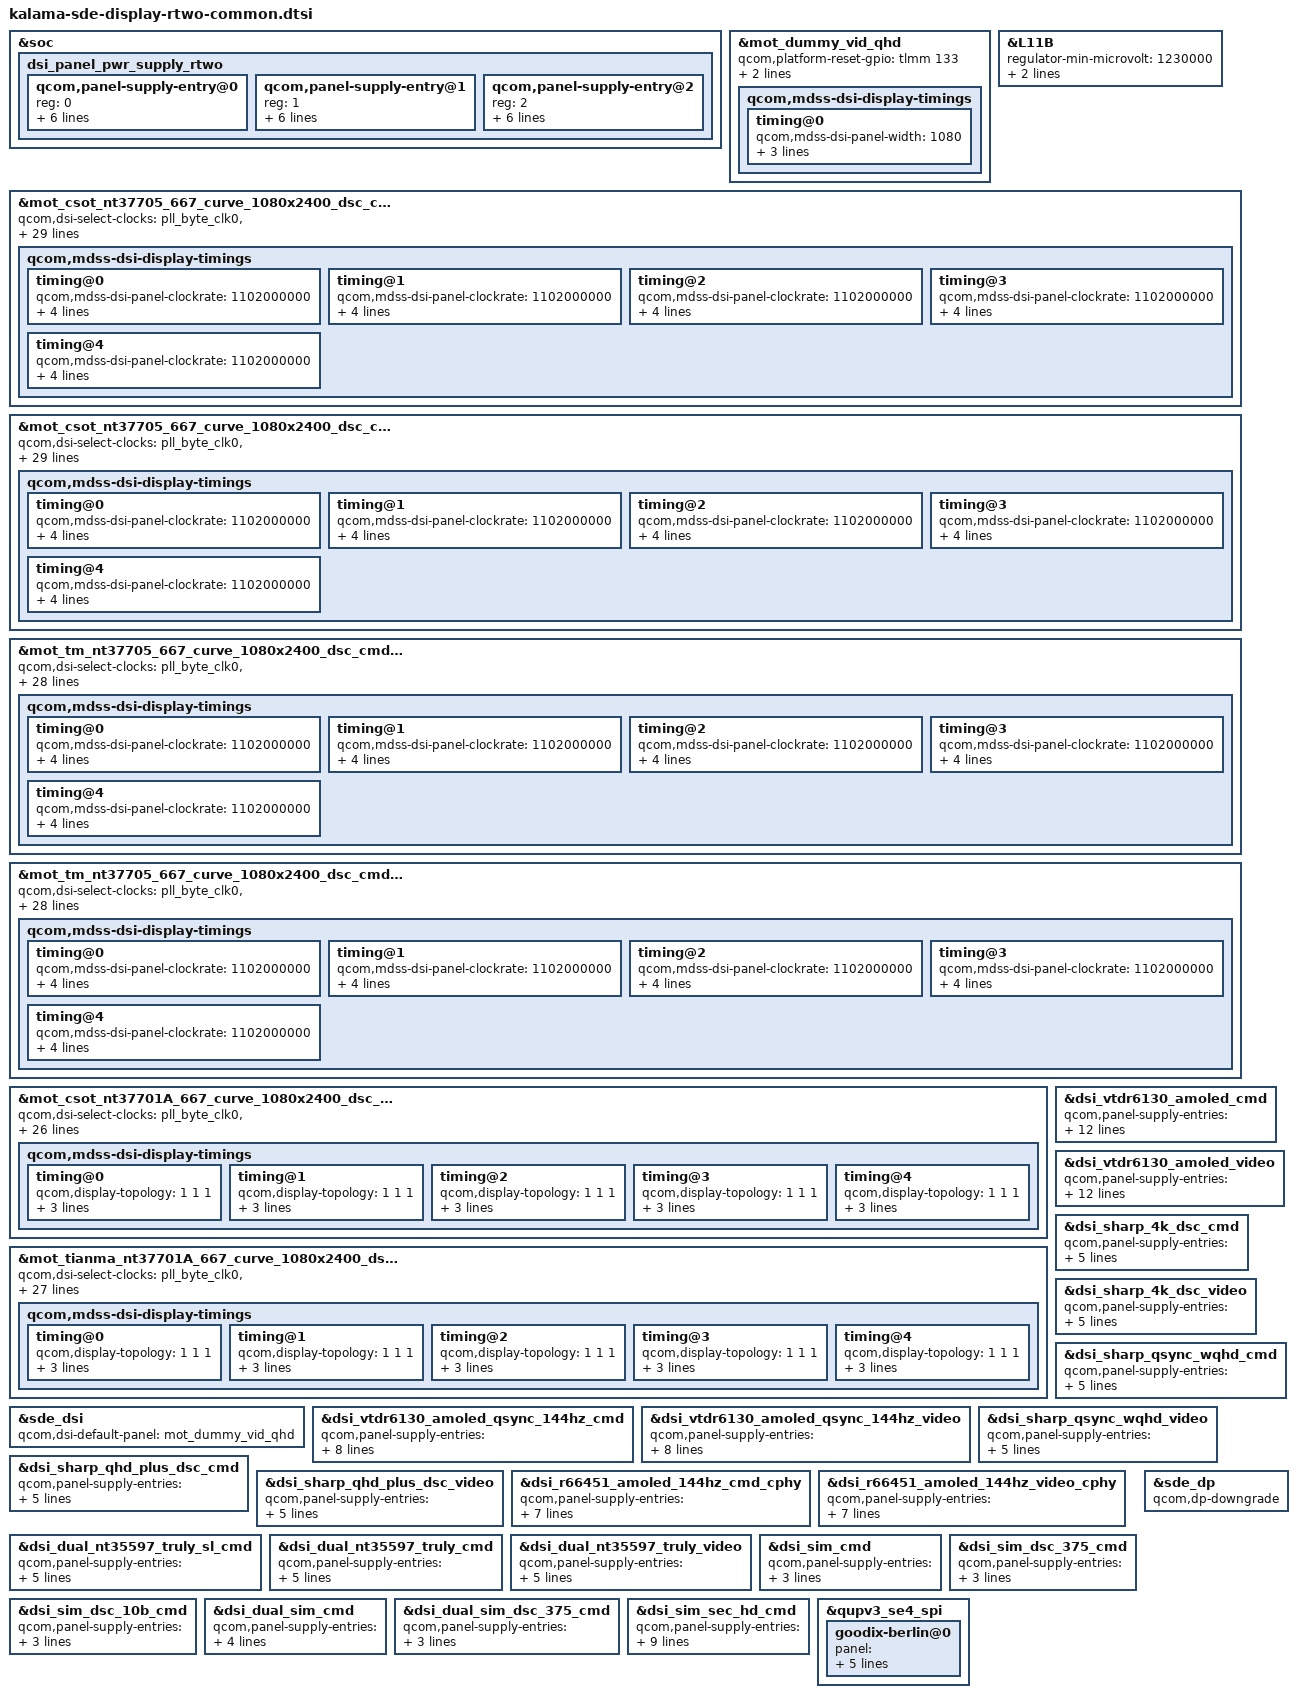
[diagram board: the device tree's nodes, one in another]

/* this is original from kalama-sde-display-mtp.dtsi */

#include "kalama-sde-display.dtsi"
#include "dsi-panel-mot-dummy-qhd-video.dtsi"
#include "dsi-panel-mot-tianma-nt37701A-667-curve-1080x2400-dsc-cmd-common.dtsi"
#include "dsi-panel-mot-csot-nt37701A-667-curve-1080x2400-dsc-cmd-common.dtsi"
#include "dsi-panel-mot-csot-nt37705-667-curve-1080x2400-dsc-cmd-common_v0.dtsi"
#include "dsi-panel-mot-csot-nt37705-667-curve-1080x2400-dsc-cmd-common_v1.dtsi"
#include "dsi-panel-mot-csot-nt37705-667-curve-1080x2400-dsc-cmd-common_v0_lhbm.dtsi"
#include "dsi-panel-mot-csot-nt37705-667-curve-1080x2400-dsc-cmd-common_v1_lhbm.dtsi"
#include "dsi-panel-mot-tm-nt37705-667-curve-1080x2400-dsc-cmd-common_v0.dtsi"
#include "dsi-panel-mot-tm-nt37705-667-curve-1080x2400-dsc-cmd-common_v0_lhbm.dtsi"
#include "dsi-panel-mot-tm-nt37705-667-curve-1080x2400-dsc-cmd-common_v1.dtsi"
#include "dsi-panel-mot-tm-nt37705-667-curve-1080x2400-dsc-cmd-common_v1_lhbm.dtsi"
&soc {
	dsi_panel_pwr_supply_rtwo: dsi_panel_pwr_supply_rtwo {
		#address-cells = <1>;
		#size-cells = <0>;

		qcom,panel-supply-entry@0 {
			reg = <0>;
			qcom,supply-name = "vddio";
			qcom,supply-min-voltage = <1800000>;
			qcom,supply-max-voltage = <1800000>;
			qcom,supply-enable-load = <200000>;
			qcom,supply-disable-load = <80>;
			qcom,supply-post-on-sleep = <0>;
		};

		qcom,panel-supply-entry@1 {
			reg = <1>;
			qcom,supply-name = "vdd";
			qcom,supply-min-voltage = <1230000>;
			qcom,supply-max-voltage = <1280000>;
			qcom,supply-enable-load = <299000>;
			qcom,supply-disable-load = <0>;
			qcom,supply-post-on-sleep = <0>;
		};

		qcom,panel-supply-entry@2 {
			reg = <2>;
			qcom,supply-name = "vci";
			qcom,supply-min-voltage = <3000000>;
			qcom,supply-max-voltage = <3000000>;
			qcom,supply-enable-load = <10000>;
			qcom,supply-disable-load = <0>;
			qcom,supply-post-on-sleep = <0>;
		};
	};

};
&mot_dummy_vid_qhd {
	qcom,mdss-dsi-display-timings {
                timing@0{
			qcom,mdss-dsi-panel-width = <1080>;
			qcom,mdss-dsi-panel-height = <2400>;
		};
	};
};

&L11B {
       regulator-min-microvolt = <1230000>;
       regulator-max-microvolt = <1280000>;
       qcom,init-voltage = <1230000>;
};

&mot_csot_nt37705_667_curve_1080x2400_dsc_cmd_v1 {
	qcom,dsi-select-clocks = "pll_byte_clk0", "pll_dsi_clk0";

	//qcom,dsi-dyn-clk-enable;

	qcom,panel-supply-entries = <&dsi_panel_pwr_supply_rtwo>;
	qcom,mdss-dsi-no-panel-on-read-support;
	qcom,mdss-dsi-bl-pmic-control-type = "bl_ctrl_dcs";
	qcom,mdss-dsi-bl-min-level = <420>;
	qcom,mdss-dsi-bl-max-level = <16380>;
	//qcom,mdss-dsi-bl-default-level = <1024>;
	qcom,mdss-brightness-max-level = <16380>;
	qcom,platform-reset-gpio = <&tlmm 133 0>;
	qcom,bl-dsc-cmd-state = "dsi_hs_mode";
	qcom,mdss-dsi-bl-inverted-dbv;
	qcom,mdss-dsi-bl-is-exponent;
	qcom,mdss-dsi-bl-double-write;

	qcom,mdss-dsi-panel-hdr-enabled;
	qcom,mdss-dsi-panel-hdr-color-primaries = <14950 15750 34000
	        16000 13000 35500 7000 2500>;
	qcom,mdss-dsi-panel-peak-brightness = <15000000>;
	qcom,mdss-dsi-panel-blackness-level = <1>;

	qcom,mdss-dsi-panel-status-check-mode = "reg_read";
	qcom,mdss-dsi-panel-status-command = [06 01 00 01 00 00 01 0a];
	qcom,mdss-dsi-panel-status-command-state = "dsi_lp_mode";
	qcom,mdss-dsi-panel-status-value = <0x9c>;
	qcom,mdss-dsi-panel-status-read-length = <1>;
	qcom,esd-check-enabled;
	qcom,mot_nt37705A_read_cellid;

	qcom,mdss-dsi-display-timings {
		timing@0 {
			qcom,mdss-dsi-panel-clockrate = <1102000000>;
			qcom,display-topology = <1 1 1>;
			qcom,default-topology-index = <0>;
			qcom,mdss-dsi-panel-phy-timings = [00 24 0A 0A 1A 24 0A
							0A 09 02 04 00 1E 0F];
		};
		timing@1 {
			qcom,mdss-dsi-panel-clockrate = <1102000000>;
			qcom,display-topology = <1 1 1>;
			qcom,default-topology-index = <0>;
			qcom,mdss-dsi-panel-phy-timings = [00 24 0A 0A 1A 24 0A
							0A 09 02 04 00 1E 0F];
		};
		timing@2 {
			qcom,mdss-dsi-panel-clockrate = <1102000000>;
			qcom,display-topology = <1 1 1>;
			qcom,default-topology-index = <0>;
			qcom,mdss-dsi-panel-phy-timings = [00 24 0A 0A 1A 24 0A
							0A 09 02 04 00 1E 0F];
		};
		timing@3 {
			qcom,mdss-dsi-panel-clockrate = <1102000000>;
			qcom,display-topology = <1 1 1>;
			qcom,default-topology-index = <0>;
			qcom,mdss-dsi-panel-phy-timings = [00 24 0A 0A 1A 24 0A
							0A 09 02 04 00 1E 0F];
		};
		timing@4 {
			qcom,mdss-dsi-panel-clockrate = <1102000000>;
			qcom,display-topology = <1 1 1>;
			qcom,default-topology-index = <0>;
			qcom,mdss-dsi-panel-phy-timings = [00 24 0A 0A 1A 24 0A
							0A 09 02 04 00 1E 0F];
		};
	};
};

&mot_csot_nt37705_667_curve_1080x2400_dsc_cmd_v0 {
	qcom,dsi-select-clocks = "pll_byte_clk0", "pll_dsi_clk0";

	//qcom,dsi-dyn-clk-enable;

	qcom,panel-supply-entries = <&dsi_panel_pwr_supply_rtwo>;
	qcom,mdss-dsi-no-panel-on-read-support;
	qcom,mdss-dsi-bl-pmic-control-type = "bl_ctrl_dcs";
	qcom,mdss-dsi-bl-min-level = <420>;
	qcom,mdss-dsi-bl-max-level = <16380>;
	//qcom,mdss-dsi-bl-default-level = <1024>;
	qcom,mdss-brightness-max-level = <16380>;
	qcom,platform-reset-gpio = <&tlmm 133 0>;
	qcom,bl-dsc-cmd-state = "dsi_hs_mode";
	qcom,mdss-dsi-bl-inverted-dbv;
	qcom,mdss-dsi-bl-is-exponent;
	qcom,mdss-dsi-bl-double-write;

	qcom,mdss-dsi-panel-hdr-enabled;
	qcom,mdss-dsi-panel-hdr-color-primaries = <14950 15750 34000
	        16000 13000 35500 7000 2500>;
	qcom,mdss-dsi-panel-peak-brightness = <15000000>;
	qcom,mdss-dsi-panel-blackness-level = <1>;

	qcom,mdss-dsi-panel-status-check-mode = "reg_read";
	qcom,mdss-dsi-panel-status-command = [06 01 00 01 00 00 01 0a];
	qcom,mdss-dsi-panel-status-command-state = "dsi_lp_mode";
	qcom,mdss-dsi-panel-status-value = <0x9c>;
	qcom,mdss-dsi-panel-status-read-length = <1>;
	qcom,esd-check-enabled;
	qcom,mot_nt37705A_read_cellid;

	qcom,mdss-dsi-display-timings {
		timing@0 {
			qcom,mdss-dsi-panel-clockrate = <1102000000>;
			qcom,display-topology = <1 1 1>;
			qcom,default-topology-index = <0>;
			qcom,mdss-dsi-panel-phy-timings = [00 24 0A 0A 1A 24 0A
							0A 09 02 04 00 1E 0F];
		};
		timing@1 {
			qcom,mdss-dsi-panel-clockrate = <1102000000>;
			qcom,display-topology = <1 1 1>;
			qcom,default-topology-index = <0>;
			qcom,mdss-dsi-panel-phy-timings = [00 24 0A 0A 1A 24 0A
							0A 09 02 04 00 1E 0F];
		};
		timing@2 {
			qcom,mdss-dsi-panel-clockrate = <1102000000>;
			qcom,display-topology = <1 1 1>;
			qcom,default-topology-index = <0>;
			qcom,mdss-dsi-panel-phy-timings = [00 24 0A 0A 1A 24 0A
							0A 09 02 04 00 1E 0F];
		};
		timing@3 {
			qcom,mdss-dsi-panel-clockrate = <1102000000>;
			qcom,display-topology = <1 1 1>;
			qcom,default-topology-index = <0>;
			qcom,mdss-dsi-panel-phy-timings = [00 24 0A 0A 1A 24 0A
							0A 09 02 04 00 1E 0F];
		};
		timing@4 {
			qcom,mdss-dsi-panel-clockrate = <1102000000>;
			qcom,display-topology = <1 1 1>;
			qcom,default-topology-index = <0>;
			qcom,mdss-dsi-panel-phy-timings = [00 24 0A 0A 1A 24 0A
							0A 09 02 04 00 1E 0F];
		};
	};
};

&mot_tm_nt37705_667_curve_1080x2400_dsc_cmd_v0 {
	qcom,dsi-select-clocks = "pll_byte_clk0", "pll_dsi_clk0";

	//qcom,dsi-dyn-clk-enable;

	qcom,panel-supply-entries = <&dsi_panel_pwr_supply_rtwo>;
	qcom,mdss-dsi-no-panel-on-read-support;
	qcom,mdss-dsi-bl-pmic-control-type = "bl_ctrl_dcs";
	qcom,mdss-dsi-bl-min-level = <420>;
	qcom,mdss-dsi-bl-max-level = <16380>;
	//qcom,mdss-dsi-bl-default-level = <1024>;
	qcom,mdss-brightness-max-level = <16380>;
	qcom,platform-reset-gpio = <&tlmm 133 0>;
	qcom,bl-dsc-cmd-state = "dsi_hs_mode";
	qcom,mdss-dsi-bl-inverted-dbv;
	qcom,mdss-dsi-bl-is-exponent;

	qcom,mdss-dsi-panel-hdr-enabled;
	qcom,mdss-dsi-panel-hdr-color-primaries = <14950 15750 34000
	        16000 13000 35500 7000 2500>;
	qcom,mdss-dsi-panel-peak-brightness = <15000000>;
	qcom,mdss-dsi-panel-blackness-level = <1>;

	qcom,mdss-dsi-panel-status-check-mode = "reg_read";
	qcom,mdss-dsi-panel-status-command = [06 01 00 01 00 00 01 0a];
	qcom,mdss-dsi-panel-status-command-state = "dsi_lp_mode";
	qcom,mdss-dsi-panel-status-value = <0x9c>;
	qcom,mdss-dsi-panel-status-read-length = <1>;
	qcom,esd-check-enabled;
	qcom,mot_nt37705A_read_cellid;

	qcom,mdss-dsi-display-timings {
		timing@0 {
			qcom,mdss-dsi-panel-clockrate = <1102000000>;
			qcom,display-topology = <1 1 1>;
			qcom,default-topology-index = <0>;
			qcom,mdss-dsi-panel-phy-timings = [00 24 0A 0A 1A 24 0A
							0A 09 02 04 00 1E 0F];
		};
		timing@1 {
			qcom,mdss-dsi-panel-clockrate = <1102000000>;
			qcom,display-topology = <1 1 1>;
			qcom,default-topology-index = <0>;
			qcom,mdss-dsi-panel-phy-timings = [00 24 0A 0A 1A 24 0A
							0A 09 02 04 00 1E 0F];
		};
		timing@2 {
			qcom,mdss-dsi-panel-clockrate = <1102000000>;
			qcom,display-topology = <1 1 1>;
			qcom,default-topology-index = <0>;
			qcom,mdss-dsi-panel-phy-timings = [00 24 0A 0A 1A 24 0A
							0A 09 02 04 00 1E 0F];
		};
		timing@3 {
			qcom,mdss-dsi-panel-clockrate = <1102000000>;
			qcom,display-topology = <1 1 1>;
			qcom,default-topology-index = <0>;
			qcom,mdss-dsi-panel-phy-timings = [00 24 0A 0A 1A 24 0A
							0A 09 02 04 00 1E 0F];
		};
		timing@4 {
			qcom,mdss-dsi-panel-clockrate = <1102000000>;
			qcom,display-topology = <1 1 1>;
			qcom,default-topology-index = <0>;
			qcom,mdss-dsi-panel-phy-timings = [00 24 0A 0A 1A 24 0A
							0A 09 02 04 00 1E 0F];
		};
	};
};

&mot_tm_nt37705_667_curve_1080x2400_dsc_cmd_v1 {
	qcom,dsi-select-clocks = "pll_byte_clk0", "pll_dsi_clk0";

	//qcom,dsi-dyn-clk-enable;

	qcom,panel-supply-entries = <&dsi_panel_pwr_supply_rtwo>;
	qcom,mdss-dsi-no-panel-on-read-support;
	qcom,mdss-dsi-bl-pmic-control-type = "bl_ctrl_dcs";
	qcom,mdss-dsi-bl-min-level = <420>;
	qcom,mdss-dsi-bl-max-level = <16380>;
	//qcom,mdss-dsi-bl-default-level = <1024>;
	qcom,mdss-brightness-max-level = <16380>;
	qcom,platform-reset-gpio = <&tlmm 133 0>;
	qcom,bl-dsc-cmd-state = "dsi_hs_mode";
	qcom,mdss-dsi-bl-inverted-dbv;
	qcom,mdss-dsi-bl-is-exponent;

	qcom,mdss-dsi-panel-hdr-enabled;
	qcom,mdss-dsi-panel-hdr-color-primaries = <14950 15750 34000
	        16000 13000 35500 7000 2500>;
	qcom,mdss-dsi-panel-peak-brightness = <15000000>;
	qcom,mdss-dsi-panel-blackness-level = <1>;

	qcom,mdss-dsi-panel-status-check-mode = "reg_read";
	qcom,mdss-dsi-panel-status-command = [06 01 00 01 00 00 01 0a];
	qcom,mdss-dsi-panel-status-command-state = "dsi_lp_mode";
	qcom,mdss-dsi-panel-status-value = <0x9c>;
	qcom,mdss-dsi-panel-status-read-length = <1>;
	qcom,esd-check-enabled;
	qcom,mot_nt37705A_read_cellid;

	qcom,mdss-dsi-display-timings {
		timing@0 {
			qcom,mdss-dsi-panel-clockrate = <1102000000>;
			qcom,display-topology = <1 1 1>;
			qcom,default-topology-index = <0>;
			qcom,mdss-dsi-panel-phy-timings = [00 24 0A 0A 1A 24 0A
							0A 09 02 04 00 1E 0F];
		};
		timing@1 {
			qcom,mdss-dsi-panel-clockrate = <1102000000>;
			qcom,display-topology = <1 1 1>;
			qcom,default-topology-index = <0>;
			qcom,mdss-dsi-panel-phy-timings = [00 24 0A 0A 1A 24 0A
							0A 09 02 04 00 1E 0F];
		};
		timing@2 {
			qcom,mdss-dsi-panel-clockrate = <1102000000>;
			qcom,display-topology = <1 1 1>;
			qcom,default-topology-index = <0>;
			qcom,mdss-dsi-panel-phy-timings = [00 24 0A 0A 1A 24 0A
							0A 09 02 04 00 1E 0F];
		};
		timing@3 {
			qcom,mdss-dsi-panel-clockrate = <1102000000>;
			qcom,display-topology = <1 1 1>;
			qcom,default-topology-index = <0>;
			qcom,mdss-dsi-panel-phy-timings = [00 24 0A 0A 1A 24 0A
							0A 09 02 04 00 1E 0F];
		};
		timing@4 {
			qcom,mdss-dsi-panel-clockrate = <1102000000>;
			qcom,display-topology = <1 1 1>;
			qcom,default-topology-index = <0>;
			qcom,mdss-dsi-panel-phy-timings = [00 24 0A 0A 1A 24 0A
							0A 09 02 04 00 1E 0F];
		};
	};
};

&mot_csot_nt37701A_667_curve_1080x2400_dsc_cmd {
	qcom,dsi-select-clocks = "pll_byte_clk0", "pll_dsi_clk0";

	//qcom,dsi-dyn-clk-enable;

	qcom,panel-supply-entries = <&dsi_panel_pwr_supply>;
	qcom,mdss-dsi-no-panel-on-read-support;
	qcom,mdss-dsi-bl-pmic-control-type = "bl_ctrl_dcs";
	qcom,mdss-dsi-bl-min-level = <9>;
	qcom,mdss-dsi-bl-max-level = <3515>;
	//qcom,mdss-dsi-bl-default-level = <1024>;
	qcom,mdss-brightness-max-level = <3515>;
	qcom,platform-reset-gpio = <&tlmm 133 0>;
	qcom,bl-dsc-cmd-state = "dsi_hs_mode";
	qcom,mdss-dsi-bl-inverted-dbv;
	qcom,mdss-dsi-bl-is-exponent;

	qcom,mdss-dsi-panel-hdr-enabled;
	qcom,mdss-dsi-panel-hdr-color-primaries = <14950 15750 34000
	        16000 13000 35500 7000 2500>;
	qcom,mdss-dsi-panel-peak-brightness = <5000000>;
	qcom,mdss-dsi-panel-blackness-level = <100>;

	qcom,mdss-dsi-panel-status-check-mode = "reg_read";
	qcom,mdss-dsi-panel-status-command = [06 01 00 01 00 00 01 0a];
	qcom,mdss-dsi-panel-status-command-state = "dsi_lp_mode";
	qcom,mdss-dsi-panel-status-value = <0x9c>;
	qcom,mdss-dsi-panel-status-read-length = <1>;
	//qcom,esd-check-enabled;

	qcom,mdss-dsi-display-timings {
		timing@0 {
			//qcom,mdss-dsi-panel-clockrate = <400000000>;
			qcom,display-topology = <1 1 1>;
			qcom,default-topology-index = <0>;
			qcom,mdss-dsi-panel-phy-timings = [00 10 03 03 11 1E 04
							04 03 02 04 00 0E 08];
		};
		timing@1 {
			//qcom,mdss-dsi-panel-clockrate = <601000000>;
			qcom,display-topology = <1 1 1>;
			qcom,default-topology-index = <0>;
			qcom,mdss-dsi-panel-phy-timings = [00 16 05 05 14 1F 06
							06 06 02 04 00 13 0A];
		};
		timing@2 {
			//qcom,mdss-dsi-panel-clockrate = <801000000>;
			qcom,display-topology = <1 1 1>;
			qcom,default-topology-index = <0>;
			qcom,mdss-dsi-panel-phy-timings = [00 1C 07 07 17 15 07
							07 08 02 04 00 18 0C];
		};
		timing@3 {
			//qcom,mdss-dsi-panel-clockrate = <951000000>;
			qcom,display-topology = <1 1 1>;
			qcom,default-topology-index = <0>;
			qcom,mdss-dsi-panel-phy-timings = [00 20 08 08 18 23 08
							08 08 02 04 00 1B 0D];
		};
		timing@4 {
			//qcom,mdss-dsi-panel-clockrate = <320000000>;
			qcom,display-topology = <1 1 1>;
			qcom,default-topology-index = <0>;
			qcom,mdss-dsi-panel-phy-timings = [00 0D 03 03 10 1D 04
							03 02 02 04 00 0C 08];
		};
	};
};

&mot_tianma_nt37701A_667_curve_1080x2400_dsc_cmd {
	qcom,dsi-select-clocks = "pll_byte_clk0", "pll_dsi_clk0";
	//qcom,dsi-select-sec-clocks = "pll_byte_clk1", "pll_dsi_clk1";

	//qcom,dsi-dyn-clk-enable;

	qcom,panel-supply-entries = <&dsi_panel_pwr_supply>;
	qcom,mdss-dsi-no-panel-on-read-support;
	qcom,mdss-dsi-bl-pmic-control-type = "bl_ctrl_dcs";
	qcom,mdss-dsi-bl-min-level = <9>;
	qcom,mdss-dsi-bl-max-level = <3515>;
	//qcom,mdss-dsi-bl-default-level = <1024>;
	qcom,mdss-brightness-max-level = <3515>;
	//qcom,backlight_map_type = <1>;
	qcom,platform-reset-gpio = <&tlmm 133 0>;
	qcom,bl-dsc-cmd-state = "dsi_hs_mode";
	qcom,mdss-dsi-bl-inverted-dbv;

	qcom,mdss-dsi-panel-hdr-enabled;
	qcom,mdss-dsi-panel-hdr-color-primaries = <14950 15750 34000
	        16000 13000 35500 7000 2500>;
	qcom,mdss-dsi-panel-peak-brightness = <5000000>;
	qcom,mdss-dsi-panel-blackness-level = <100>;

	qcom,mdss-dsi-panel-status-check-mode = "reg_read";
	qcom,mdss-dsi-panel-status-command = [06 01 00 01 00 00 01 0a];
	qcom,mdss-dsi-panel-status-command-state = "dsi_lp_mode";
	qcom,mdss-dsi-panel-status-value = <0x9c>;
	qcom,mdss-dsi-panel-status-read-length = <1>;
	qcom,esd-check-enabled;
	qcom,mdss-dsi-bl-is-exponent;

	qcom,mdss-dsi-display-timings {
		timing@0 {
			//qcom,mdss-dsi-panel-clockrate = <400000000>;
			qcom,display-topology = <1 1 1>;
			qcom,default-topology-index = <0>;
			qcom,mdss-dsi-panel-phy-timings = [00 10 03 03 11 1E 04
							04 03 02 04 00 0E 08];
		};
		timing@1 {
			//qcom,mdss-dsi-panel-clockrate = <601000000>;
			qcom,display-topology = <1 1 1>;
			qcom,default-topology-index = <0>;
			qcom,mdss-dsi-panel-phy-timings = [00 16 05 05 14 1F 06
							06 06 02 04 00 13 0A];
		};
		timing@2 {
			//qcom,mdss-dsi-panel-clockrate = <801000000>;
			qcom,display-topology = <1 1 1>;
			qcom,default-topology-index = <0>;
			qcom,mdss-dsi-panel-phy-timings = [00 1C 07 07 17 15 07
							07 08 02 04 00 18 0C];
		};
		timing@3 {
			//qcom,mdss-dsi-panel-clockrate = <951000000>;
			qcom,display-topology = <1 1 1>;
			qcom,default-topology-index = <0>;
			qcom,mdss-dsi-panel-phy-timings = [00 20 08 08 18 23 08
							08 08 02 04 00 1B 0D];
		};
		timing@4 {
			//qcom,mdss-dsi-panel-clockrate = <320000000>;
			qcom,display-topology = <1 1 1>;
			qcom,default-topology-index = <0>;
			qcom,mdss-dsi-panel-phy-timings = [00 0D 03 03 10 1D 04
							03 02 02 04 00 0C 08];
		};
	};
};

&mot_dummy_vid_qhd {
	qcom,platform-reset-gpio = <&tlmm 133 0>;

	qcom,dsi-select-clocks = "pll_byte_clk0", "pll_dsi_clk0";
	qcom,mdss-dsi-display-timings {
		timing@0 {
			qcom,display-topology = <1 0 1>;
			qcom,default-topology-index = <0>;
		};
	};
};

&sde_dsi {
	qcom,dsi-default-panel = <&mot_dummy_vid_qhd>;
};

&dsi_vtdr6130_amoled_cmd {
	qcom,panel-supply-entries = <&dsi_panel_pwr_supply>;
	qcom,panel-sec-supply-entries = <&dsi_panel_pwr_supply_sim>;
	qcom,mdss-dsi-bl-pmic-control-type = "bl_ctrl_dcs";
	qcom,mdss-dsi-sec-bl-pmic-control-type = "bl_ctrl_dcs";
	qcom,mdss-dsi-bl-min-level = <10>;
	qcom,mdss-dsi-bl-max-level = <4095>;
	qcom,mdss-brightness-max-level = <8191>;
	qcom,mdss-dsi-bl-inverted-dbv;
	qcom,platform-reset-gpio = <&tlmm 133 0>;
};

&dsi_vtdr6130_amoled_video {
	qcom,panel-supply-entries = <&dsi_panel_pwr_supply>;
	qcom,panel-sec-supply-entries = <&dsi_panel_pwr_supply_sim>;
	qcom,mdss-dsi-bl-pmic-control-type = "bl_ctrl_dcs";
	qcom,mdss-dsi-sec-bl-pmic-control-type = "bl_ctrl_dcs";
	qcom,mdss-dsi-bl-min-level = <10>;
	qcom,mdss-dsi-bl-max-level = <4095>;
	qcom,mdss-brightness-max-level = <8191>;
	qcom,mdss-dsi-bl-inverted-dbv;
	qcom,platform-reset-gpio = <&tlmm 133 0>;
};

&dsi_vtdr6130_amoled_qsync_144hz_cmd {
	qcom,panel-supply-entries = <&dsi_panel_pwr_supply>;
	qcom,mdss-dsi-bl-pmic-control-type = "bl_ctrl_dcs";
	qcom,mdss-dsi-bl-min-level = <10>;
	qcom,mdss-dsi-bl-max-level = <4095>;
	qcom,mdss-brightness-max-level = <8191>;
	qcom,mdss-dsi-bl-inverted-dbv;
	qcom,platform-reset-gpio = <&tlmm 133 0>;
};

&dsi_vtdr6130_amoled_qsync_144hz_video {
	qcom,panel-supply-entries = <&dsi_panel_pwr_supply>;
	qcom,mdss-dsi-bl-pmic-control-type = "bl_ctrl_dcs";
	qcom,mdss-dsi-bl-min-level = <10>;
	qcom,mdss-dsi-bl-max-level = <4095>;
	qcom,mdss-brightness-max-level = <8191>;
	qcom,mdss-dsi-bl-inverted-dbv;
	qcom,platform-reset-gpio = <&tlmm 133 0>;
};

&dsi_sharp_4k_dsc_cmd {
	qcom,panel-supply-entries = <&dsi_panel_pwr_supply_sim>;
	qcom,mdss-dsi-bl-pmic-control-type = "bl_ctrl_external";
	qcom,mdss-dsi-bl-min-level = <1>;
	qcom,mdss-dsi-bl-max-level = <4095>;
};

&dsi_sharp_4k_dsc_video {
	qcom,panel-supply-entries = <&dsi_panel_pwr_supply_sim>;
	qcom,mdss-dsi-bl-pmic-control-type = "bl_ctrl_external";
	qcom,mdss-dsi-bl-min-level = <1>;
	qcom,mdss-dsi-bl-max-level = <4095>;
};

&dsi_sharp_qsync_wqhd_cmd {
	qcom,panel-supply-entries = <&dsi_panel_pwr_supply_sim>;
	qcom,mdss-dsi-bl-pmic-control-type = "bl_ctrl_external";
	qcom,mdss-dsi-bl-min-level = <1>;
	qcom,mdss-dsi-bl-max-level = <4095>;
};

&dsi_sharp_qsync_wqhd_video {
	qcom,panel-supply-entries = <&dsi_panel_pwr_supply_sim>;
	qcom,mdss-dsi-bl-pmic-control-type = "bl_ctrl_external";
	qcom,mdss-dsi-bl-min-level = <1>;
	qcom,mdss-dsi-bl-max-level = <4095>;
};

&dsi_sharp_qhd_plus_dsc_cmd {
	qcom,panel-supply-entries = <&dsi_panel_pwr_supply_sim>;
	qcom,mdss-dsi-bl-pmic-control-type = "bl_ctrl_external";
	qcom,mdss-dsi-bl-min-level = <1>;
	qcom,mdss-dsi-bl-max-level = <4095>;
};

&dsi_sharp_qhd_plus_dsc_video {
	qcom,panel-supply-entries = <&dsi_panel_pwr_supply_sim>;
	qcom,mdss-dsi-bl-pmic-control-type = "bl_ctrl_external";
	qcom,mdss-dsi-bl-min-level = <1>;
	qcom,mdss-dsi-bl-max-level = <4095>;
};

&dsi_r66451_amoled_144hz_cmd_cphy {
	qcom,panel-supply-entries = <&dsi_panel_pwr_supply_sim>;
	qcom,mdss-dsi-bl-pmic-control-type = "bl_ctrl_dcs";
	qcom,mdss-dsi-bl-min-level = <10>;
	qcom,mdss-dsi-bl-max-level = <4095>;
	qcom,mdss-brightness-max-level = <8191>;
	qcom,mdss-dsi-bl-inverted-dbv;
};

&dsi_r66451_amoled_144hz_video_cphy {
	qcom,panel-supply-entries = <&dsi_panel_pwr_supply_sim>;
	qcom,mdss-dsi-bl-pmic-control-type = "bl_ctrl_dcs";
	qcom,mdss-dsi-bl-min-level = <10>;
	qcom,mdss-dsi-bl-max-level = <4095>;
	qcom,mdss-brightness-max-level = <8191>;
	qcom,mdss-dsi-bl-inverted-dbv;
};

&dsi_dual_nt35597_truly_sl_cmd {
	qcom,panel-supply-entries = <&dsi_panel_pwr_supply_sim>;
	qcom,mdss-dsi-bl-pmic-control-type = "bl_ctrl_external";
	qcom,mdss-dsi-bl-min-level = <1>;
	qcom,mdss-dsi-bl-max-level = <4095>;
};

&dsi_dual_nt35597_truly_cmd {
	qcom,panel-supply-entries = <&dsi_panel_pwr_supply_sim>;
	qcom,mdss-dsi-bl-pmic-control-type = "bl_ctrl_external";
	qcom,mdss-dsi-bl-min-level = <1>;
	qcom,mdss-dsi-bl-max-level = <4095>;
};

&dsi_dual_nt35597_truly_video {
	qcom,panel-supply-entries = <&dsi_panel_pwr_supply_sim>;
	qcom,mdss-dsi-bl-pmic-control-type = "bl_ctrl_external";
	qcom,mdss-dsi-bl-min-level = <1>;
	qcom,mdss-dsi-bl-max-level = <4095>;
};

&dsi_sim_cmd {
	qcom,panel-supply-entries = <&dsi_panel_pwr_supply_sim>;
	qcom,mdss-dsi-bl-pmic-control-type = "bl_ctrl_dcs";
};

&dsi_sim_dsc_375_cmd {
	qcom,panel-supply-entries = <&dsi_panel_pwr_supply_sim>;
	qcom,mdss-dsi-bl-pmic-control-type = "bl_ctrl_dcs";
};

&dsi_sim_dsc_10b_cmd {
	qcom,panel-supply-entries = <&dsi_panel_pwr_supply_sim>;
	qcom,mdss-dsi-bl-pmic-control-type = "bl_ctrl_dcs";
};

&dsi_dual_sim_cmd {
	qcom,panel-supply-entries = <&dsi_panel_pwr_supply_sim>;
	qcom,mdss-dsi-bl-pmic-control-type = "bl_ctrl_dcs";
	qcom,bl-dsc-cmd-state = "dsi_lp_mode";
};

&dsi_dual_sim_dsc_375_cmd {
	qcom,panel-supply-entries = <&dsi_panel_pwr_supply_sim>;
	qcom,mdss-dsi-bl-pmic-control-type = "bl_ctrl_dcs";
};

&dsi_sim_sec_hd_cmd {
	qcom,panel-supply-entries = <&dsi_panel_pwr_supply_sim>;
	qcom,panel-sec-supply-entries = <&dsi_panel_pwr_supply>;
	qcom,mdss-dsi-bl-pmic-control-type = "bl_ctrl_dcs";
	qcom,mdss-dsi-sec-bl-pmic-control-type = "bl_ctrl_dcs";
	qcom,mdss-dsi-bl-min-level = <1>;
	qcom,mdss-dsi-bl-max-level = <1023>;
};

&qupv3_se4_spi {
    goodix-berlin@0 {
        panel = <&mot_csot_nt37701A_667_curve_1080x2400_dsc_cmd
                &mot_csot_nt37705_667_curve_1080x2400_dsc_cmd_v0
                &mot_csot_nt37705_667_curve_1080x2400_dsc_cmd_v1
                &mot_tm_nt37705_667_curve_1080x2400_dsc_cmd_v0
                &mot_tm_nt37705_667_curve_1080x2400_dsc_cmd_v1>;
    };
};

&sde_dp {

	//mmi,aux-switch-enable-gpio = <&tlmm 2 0x00>;
	//mmi,aux-switch-flip-gpio = <&tlmm 71 0x00>;
	qcom,dp-downgrade;

       /delete-property/ qcom,mst-enable;
};
